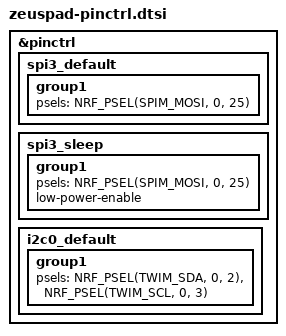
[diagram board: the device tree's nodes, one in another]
/*
 * Copyright (c) 2022 The ZMK Contributors
 * SPDX-License-Identifier: MIT
 */

 &pinctrl {
     spi3_default: spi3_default {
         group1 {
             psels = <NRF_PSEL(SPIM_MOSI, 0, 25)>;
         };
     };

     spi3_sleep: spi3_sleep {
         group1 {
             psels = <NRF_PSEL(SPIM_MOSI, 0, 25)>;
             low-power-enable;
         };
     };

     i2c0_default: i2c0_default {
          group1 {
                  psels = <NRF_PSEL(TWIM_SDA, 0, 2)>,
                          <NRF_PSEL(TWIM_SCL, 0, 3)>;
          };
     };
 };
